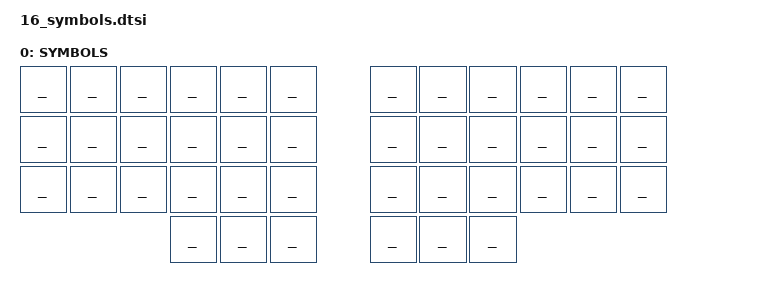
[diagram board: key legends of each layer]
/**
 * Symbols 
 */
/ {
    keymap {
        compatible = "zmk,keymap";
    symbols       {
        display-name = "SYMBOLS";
        bindings = <
// clang-format off
// ╭───────────────┬───────────────┬───────────────┬───────────────┬───────────────┬───────────────╮   ╭───────────────┬───────────────┬───────────────┬───────────────┬───────────────┬───────────────╮
// │0/LT5          │1/LT4          │2/LT3          │3/LT2          │4/LT1          │5/LT0          │   │6/RT0          │7/RT1          │8/RT2          │9/RT3          │10/RT4         │11/RT5         │
    ___             ___             ___             ___             ___             ___                 ___             ___             ___             ___             ___             ___
// ├───────────────├───────────────┼───────────────┼───────────────┼───────────────┼───────────────┤   ├───────────────├───────────────┼───────────────┼───────────────┼───────────────┼───────────────┤
// │12/LM5         │13/LM4         │14/LM3         │15/LM2         │16/LM1         │17/LM0         │   │18/RM0         │19/RM1         │20/RM2         │21/RM3         │22/RM4         │23/RM5         │
    ___             ___             ___             ___             ___             ___                 ___             ___             ___             ___             ___             ___
// ├───────────────├───────────────┼───────────────┼───────────────┼───────────────┼───────────────┤   ├───────────────├───────────────┼───────────────┼───────────────┼───────────────┼───────────────┤
// │24/LB5         │25/LB4         │26/LB3         │27/LB2         │28/LB1         │29/LB0         │   │30/RB0         │31/RB1         │32/RB2         │33/RB3         │34/RB4         │35/RB5         │
    ___             ___             ___             ___             ___             ___                 ___             ___             ___             ___             ___             ___
// ╰───────────────┴───────────────┴───────────────┼───────────────┼───────────────┼───────────────┤   ├───────────────├───────────────┼───────────────┼───────────────┴───────────────┴───────────────╯
//                                                 │36/LH2         │37/LH1         │38/LH0         │   │39/RH0         │40/RH1         │41/RH2         │
                                                    ___             ___             ___                 ___             ___             ___
//                                                 ╰───────────────┴───────────────┴───────────────╯   ╰───────────────┴───────────────┴───────────────╯
      >;
    };
  };
};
